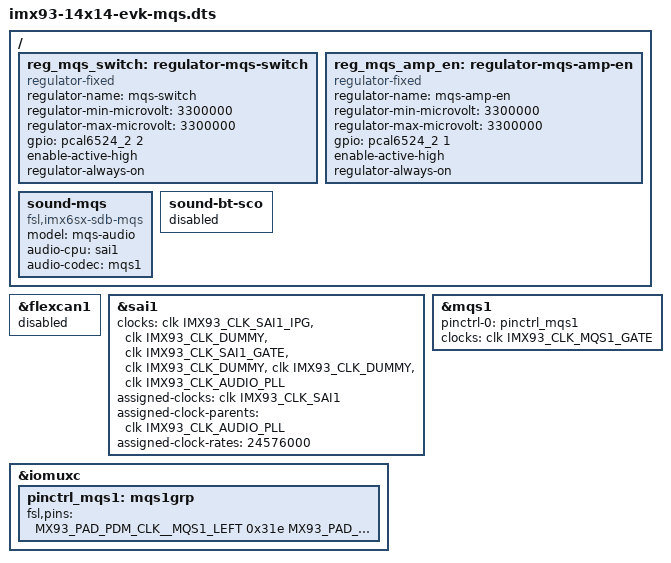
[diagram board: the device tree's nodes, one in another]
// SPDX-License-Identifier: (GPL-2.0+ OR MIT)
/*
 * Copyright 2023 NXP
 */

#include "imx93-14x14-evk.dts"

/ {
	reg_mqs_switch: regulator-mqs-switch {
		compatible = "regulator-fixed";
		regulator-name = "mqs-switch";
		regulator-min-microvolt = <3300000>;
		regulator-max-microvolt = <3300000>;
		gpio = <&pcal6524_2 2 GPIO_ACTIVE_HIGH>;
		enable-active-high;
		regulator-always-on;
	};

	reg_mqs_amp_en: regulator-mqs-amp-en {
		compatible = "regulator-fixed";
		regulator-name = "mqs-amp-en";
		regulator-min-microvolt = <3300000>;
		regulator-max-microvolt = <3300000>;
		gpio = <&pcal6524_2 1 GPIO_ACTIVE_HIGH>;
		enable-active-high;
		regulator-always-on;
	};

	sound-mqs {
		compatible = "fsl,imx6sx-sdb-mqs",
			     "fsl,imx-audio-mqs";
		model = "mqs-audio";
		audio-cpu = <&sai1>;
		audio-codec = <&mqs1>;
	};

	sound-bt-sco {
		status = "disabled";
	};
};

&flexcan1 {
	status = "disabled";
};

&sai1 {
	#sound-dai-cells = <0>;
	clocks = <&clk IMX93_CLK_SAI1_IPG>, <&clk IMX93_CLK_DUMMY>,
		 <&clk IMX93_CLK_SAI1_GATE>, <&clk IMX93_CLK_DUMMY>,
		 <&clk IMX93_CLK_DUMMY>, <&clk IMX93_CLK_AUDIO_PLL>;
	clock-names = "bus", "mclk0", "mclk1", "mclk2", "mclk3", "pll8k";
	assigned-clocks = <&clk IMX93_CLK_SAI1>;
	assigned-clock-parents = <&clk IMX93_CLK_AUDIO_PLL>;
	assigned-clock-rates = <24576000>;
	status = "okay";
};

&mqs1 {
	pinctrl-names = "default";
	pinctrl-0 = <&pinctrl_mqs1>;
	clocks = <&clk IMX93_CLK_MQS1_GATE>;
	clock-names = "mclk";
	status = "okay";
};

&iomuxc {
	pinctrl_mqs1: mqs1grp {
		fsl,pins = <
			MX93_PAD_PDM_CLK__MQS1_LEFT		0x31e
			MX93_PAD_PDM_BIT_STREAM0__MQS1_RIGHT	0x31e
		>;
	};
};
